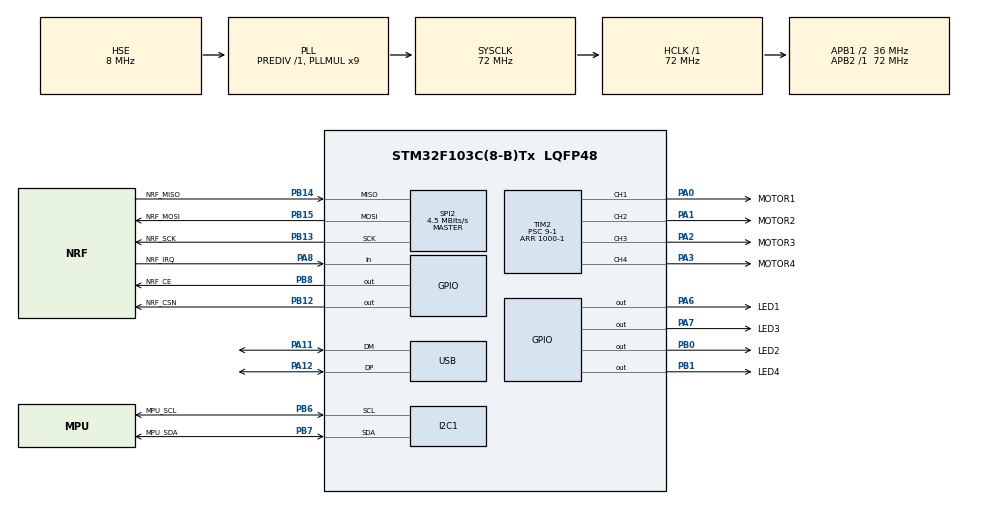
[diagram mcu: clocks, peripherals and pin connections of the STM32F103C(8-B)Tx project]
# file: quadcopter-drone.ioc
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Dma.I2C1_RX.0.Direction=DMA_PERIPH_TO_MEMORY
Dma.I2C1_RX.0.Instance=DMA1_Channel7
Dma.I2C1_RX.0.MemDataAlignment=DMA_MDATAALIGN_BYTE
Dma.I2C1_RX.0.MemInc=DMA_MINC_ENABLE
Dma.I2C1_RX.0.Mode=DMA_NORMAL
Dma.I2C1_RX.0.PeriphDataAlignment=DMA_PDATAALIGN_BYTE
Dma.I2C1_RX.0.PeriphInc=DMA_PINC_DISABLE
Dma.I2C1_RX.0.Priority=DMA_PRIORITY_HIGH
Dma.I2C1_TX.1.Direction=DMA_MEMORY_TO_PERIPH
Dma.I2C1_TX.1.Instance=DMA1_Channel6
Dma.I2C1_TX.1.MemDataAlignment=DMA_MDATAALIGN_BYTE
Dma.I2C1_TX.1.MemInc=DMA_MINC_ENABLE
Dma.I2C1_TX.1.Mode=DMA_NORMAL
Dma.I2C1_TX.1.PeriphDataAlignment=DMA_PDATAALIGN_BYTE
Dma.I2C1_TX.1.PeriphInc=DMA_PINC_DISABLE
Dma.I2C1_TX.1.Priority=DMA_PRIORITY_HIGH
Dma.Request0=I2C1_RX
Dma.Request1=I2C1_TX
I2C1.I2C_Mode=I2C_Standard
Mcu.Family=STM32F1
Mcu.Name=STM32F103C(8-B)Tx
Mcu.Package=LQFP48
NVIC.DMA1_Channel6_IRQn=true\:0\:0\:false\:false\:true\:false\:true\:true
NVIC.DMA1_Channel7_IRQn=true\:0\:0\:false\:false\:true\:false\:true\:true
NVIC.I2C1_ER_IRQn=true\:0\:0\:false\:false\:true\:true\:true\:true
NVIC.I2C1_EV_IRQn=true\:0\:0\:false\:false\:true\:true\:true\:true
NVIC.PriorityGroup=NVIC_PRIORITYGROUP_2
NVIC.TIM1_UP_IRQn=true\:0\:0\:false\:false\:true\:true\:true\:true
NVIC.USB_LP_CAN1_RX0_IRQn=true\:0\:0\:false\:false\:true\:true\:true\:true
PA0-WKUP.GPIO_Label=MOTOR1
PA0-WKUP.GPIO_Speed=GPIO_SPEED_FREQ_HIGH
PA0-WKUP.Signal=S_TIM2_CH1_ETR
PA1.GPIO_Label=MOTOR2
PA1.GPIO_Speed=GPIO_SPEED_FREQ_HIGH
PA1.Signal=S_TIM2_CH2
PA11.Mode=Device
PA11.Signal=USB_DM
PA12.Mode=Device
PA12.Signal=USB_DP
PA13.Mode=JTAG_4_pins
PA13.Signal=SYS_JTMS-SWDIO
PA14.Mode=JTAG_4_pins
PA14.Signal=SYS_JTCK-SWCLK
PA15.Mode=JTAG_4_pins
PA15.Signal=SYS_JTDI
PA2.GPIO_Label=MOTOR3
PA2.GPIO_Speed=GPIO_SPEED_FREQ_HIGH
PA2.Signal=S_TIM2_CH3
PA3.GPIO_Label=MOTOR4
PA3.GPIO_Speed=GPIO_SPEED_FREQ_HIGH
PA3.Signal=S_TIM2_CH4
PA6.GPIO_Label=LED1
PA6.GPIO_PuPd=GPIO_PULLDOWN
PA6.Signal=GPIO_Output
PA7.GPIO_Label=LED3
PA7.GPIO_PuPd=GPIO_PULLDOWN
PA7.Signal=GPIO_Output
PA8.GPIO_Label=NRF_IRQ
PA8.GPIO_PuPd=GPIO_PULLUP
PA8.Signal=GPIO_Input
PB0.GPIO_Label=LED2
PB0.GPIO_PuPd=GPIO_PULLDOWN
PB0.Signal=GPIO_Output
PB1.GPIO_Label=LED4
PB1.GPIO_PuPd=GPIO_PULLDOWN
PB1.Signal=GPIO_Output
PB12.GPIO_Label=NRF_CSN
PB12.GPIO_Speed=GPIO_SPEED_FREQ_HIGH
PB12.PinState=GPIO_PIN_SET
PB12.Signal=GPIO_Output
PB13.GPIO_Label=NRF_SCK
PB13.Mode=Full_Duplex_Master
PB13.Signal=SPI2_SCK
PB14.GPIO_Label=NRF_MISO
PB14.Mode=Full_Duplex_Master
PB14.Signal=SPI2_MISO
PB15.GPIO_Label=NRF_MOSI
PB15.Mode=Full_Duplex_Master
PB15.Signal=SPI2_MOSI
PB3.Mode=JTAG_4_pins
PB3.Signal=SYS_JTDO-TRACESWO
PB6.GPIO_Label=MPU_SCL
PB6.Mode=I2C
PB6.Signal=I2C1_SCL
PB7.GPIO_Label=MPU_SDA
PB7.Mode=I2C
PB7.Signal=I2C1_SDA
PB8.GPIO_Label=NRF_CE
PB8.GPIO_Speed=GPIO_SPEED_FREQ_HIGH
PB8.PinState=GPIO_PIN_SET
PB8.Signal=GPIO_Output
PC14-OSC32_IN.Mode=LSE-External-Oscillator
PC14-OSC32_IN.Signal=RCC_OSC32_IN
PC15-OSC32_OUT.Mode=LSE-External-Oscillator
PC15-OSC32_OUT.Signal=RCC_OSC32_OUT
PD0-OSC_IN.Mode=HSE-External-Oscillator
PD0-OSC_IN.Signal=RCC_OSC_IN
PD1-OSC_OUT.Mode=HSE-External-Oscillator
PD1-OSC_OUT.Signal=RCC_OSC_OUT
ProjectManager.HeapSize=0x600
ProjectManager.StackSize=0x400
ProjectManager.TargetToolchain=MDK-ARM V5.32
RCC.AHBFreq_Value=72000000
RCC.APB1CLKDivider=RCC_HCLK_DIV2
RCC.APB1Freq_Value=36000000
RCC.APB1TimFreq_Value=72000000
RCC.APB2Freq_Value=72000000
RCC.APB2TimFreq_Value=72000000
RCC.HCLKFreq_Value=72000000
RCC.PLLMUL=RCC_PLL_MUL9
RCC.PLLSourceVirtual=RCC_PLLSOURCE_HSE
RCC.SYSCLKFreq_VALUE=72000000
RCC.SYSCLKSource=RCC_SYSCLKSOURCE_PLLCLK
RCC.USBFreq_Value=48000000
RCC.USBPrescaler=RCC_USBCLKSOURCE_PLL_DIV1_5
SH.S_TIM2_CH1_ETR.0=TIM2_CH1,PWM Generation1 CH1
SH.S_TIM2_CH2.0=TIM2_CH2,PWM Generation2 CH2
SH.S_TIM2_CH3.0=TIM2_CH3,PWM Generation3 CH3
SH.S_TIM2_CH4.0=TIM2_CH4,PWM Generation4 CH4
SPI2.BaudRatePrescaler=SPI_BAUDRATEPRESCALER_8
SPI2.CalculateBaudRate=4.5 MBits/s
SPI2.Direction=SPI_DIRECTION_2LINES
SPI2.Mode=SPI_MODE_MASTER
SPI2.VirtualType=VM_MASTER
TIM1.Period=300-1
TIM1.Prescaler=720-1
TIM2.Channel-PWM\ Generation1\ CH1=TIM_CHANNEL_1
TIM2.Channel-PWM\ Generation2\ CH2=TIM_CHANNEL_2
TIM2.Channel-PWM\ Generation3\ CH3=TIM_CHANNEL_3
TIM2.Channel-PWM\ Generation4\ CH4=TIM_CHANNEL_4
TIM2.Period=1000-1
TIM2.Prescaler=9-1
USB_DEVICE.CLASS_NAME_FS=CUSTOM_HID
USB_DEVICE.CUSTOM_HID_FS_BINTERVAL=0x01
USB_DEVICE.PID_CUSTOMHID_FS=0xA001
USB_DEVICE.USBD_CUSTOMHID_OUTREPORT_BUF_SIZE=64
USB_DEVICE.USBD_CUSTOM_HID_REPORT_DESC_SIZE=34
USB_DEVICE.VID=0x0483
USB_DEVICE.VirtualMode=CustomHid
USB_DEVICE.VirtualModeFS=Custom_Hid_FS
VP_TIM1_VS_ClockSourceINT.Mode=Internal
VP_TIM2_VS_ClockSourceINT.Mode=Internal
VP_USB_DEVICE_VS_USB_DEVICE_CUSTOM_HID_FS.Mode=CUSTOM_HID_FS
board=custom

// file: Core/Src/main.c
/* USER CODE BEGIN Header */
/**
  ******************************************************************************
  * @file           : main.c
  * @brief          : Main program body
  ******************************************************************************
  * @attention
  *
  * Copyright (c) 2025 STMicroelectronics.
  * All rights reserved.
  *
  * This software is licensed under terms that can be found in the LICENSE file
  * in the root directory of this software component.
  * If no LICENSE file comes with this software, it is provided AS-IS.
  *
  ******************************************************************************
  */
/* USER CODE END Header */
#include "main.h"
#include "dma.h"
#include "i2c.h"
#include "spi.h"
#include "tim.h"
#include "usb_device.h"
#include "gpio.h"

/* USER CODE BEGIN Includes */
#include "ALL_DEFINE.h"
/* USER CODE END Includes */

void SystemClock_Config(void);

int main(void)
{

  /* MCU Configuration--------------------------------------------------------*/

  /* Reset of all peripherals, Initializes the Flash interface and the Systick. */
  HAL_Init();

  /* Configure the system clock */
  SystemClock_Config();

  /* Initialize all configured peripherals */
  MX_GPIO_Init();
  MX_DMA_Init();
  MX_TIM2_Init();
  MX_USB_DEVICE_Init();
  MX_TIM1_Init();
  MX_I2C1_Init();
  MX_SPI2_Init();
  /* USER CODE BEGIN 2 */
  All_Init();
  /* USER CODE END 2 */

  /* Infinite loop */
  /* USER CODE BEGIN WHILE */
  while (1) {
    if (taskState.ANTO_RUN == RUN) {
      taskState.ANTO_RUN = STOP;
      ANTO_polling();
    }

    Pilot_LED();
    /* USER CODE END WHILE */

  }
}

void SystemClock_Config(void)
{
  RCC_OscInitTypeDef RCC_OscInitStruct = {0};
  RCC_ClkInitTypeDef RCC_ClkInitStruct = {0};
  RCC_PeriphCLKInitTypeDef PeriphClkInit = {0};

  /** Initializes the RCC Oscillators according to the specified parameters
  * in the RCC_OscInitTypeDef structure.
  */
  RCC_OscInitStruct.OscillatorType = RCC_OSCILLATORTYPE_HSE;
  RCC_OscInitStruct.HSEState = RCC_HSE_ON;
  RCC_OscInitStruct.HSEPredivValue = RCC_HSE_PREDIV_DIV1;
  RCC_OscInitStruct.HSIState = RCC_HSI_ON;
  RCC_OscInitStruct.PLL.PLLState = RCC_PLL_ON;
  RCC_OscInitStruct.PLL.PLLSource = RCC_PLLSOURCE_HSE;
  RCC_OscInitStruct.PLL.PLLMUL = RCC_PLL_MUL9;
  if (HAL_RCC_OscConfig(&RCC_OscInitStruct) != HAL_OK)
  {
    Error_Handler();
  }

  /** Initializes the CPU, AHB and APB buses clocks
  */
  RCC_ClkInitStruct.ClockType = RCC_CLOCKTYPE_HCLK|RCC_CLOCKTYPE_SYSCLK
                              |RCC_CLOCKTYPE_PCLK1|RCC_CLOCKTYPE_PCLK2;
  RCC_ClkInitStruct.SYSCLKSource = RCC_SYSCLKSOURCE_PLLCLK;
  RCC_ClkInitStruct.AHBCLKDivider = RCC_SYSCLK_DIV1;
  RCC_ClkInitStruct.APB1CLKDivider = RCC_HCLK_DIV2;
  RCC_ClkInitStruct.APB2CLKDivider = RCC_HCLK_DIV1;

  if (HAL_RCC_ClockConfig(&RCC_ClkInitStruct, FLASH_LATENCY_2) != HAL_OK)
  {
    Error_Handler();
  }
  PeriphClkInit.PeriphClockSelection = RCC_PERIPHCLK_USB;
  PeriphClkInit.UsbClockSelection = RCC_USBCLKSOURCE_PLL_DIV1_5;
  if (HAL_RCCEx_PeriphCLKConfig(&PeriphClkInit) != HAL_OK)
  {
    Error_Handler();
  }
}

void Error_Handler(void)
{
  __disable_irq();
  while (1) {
  }
}
